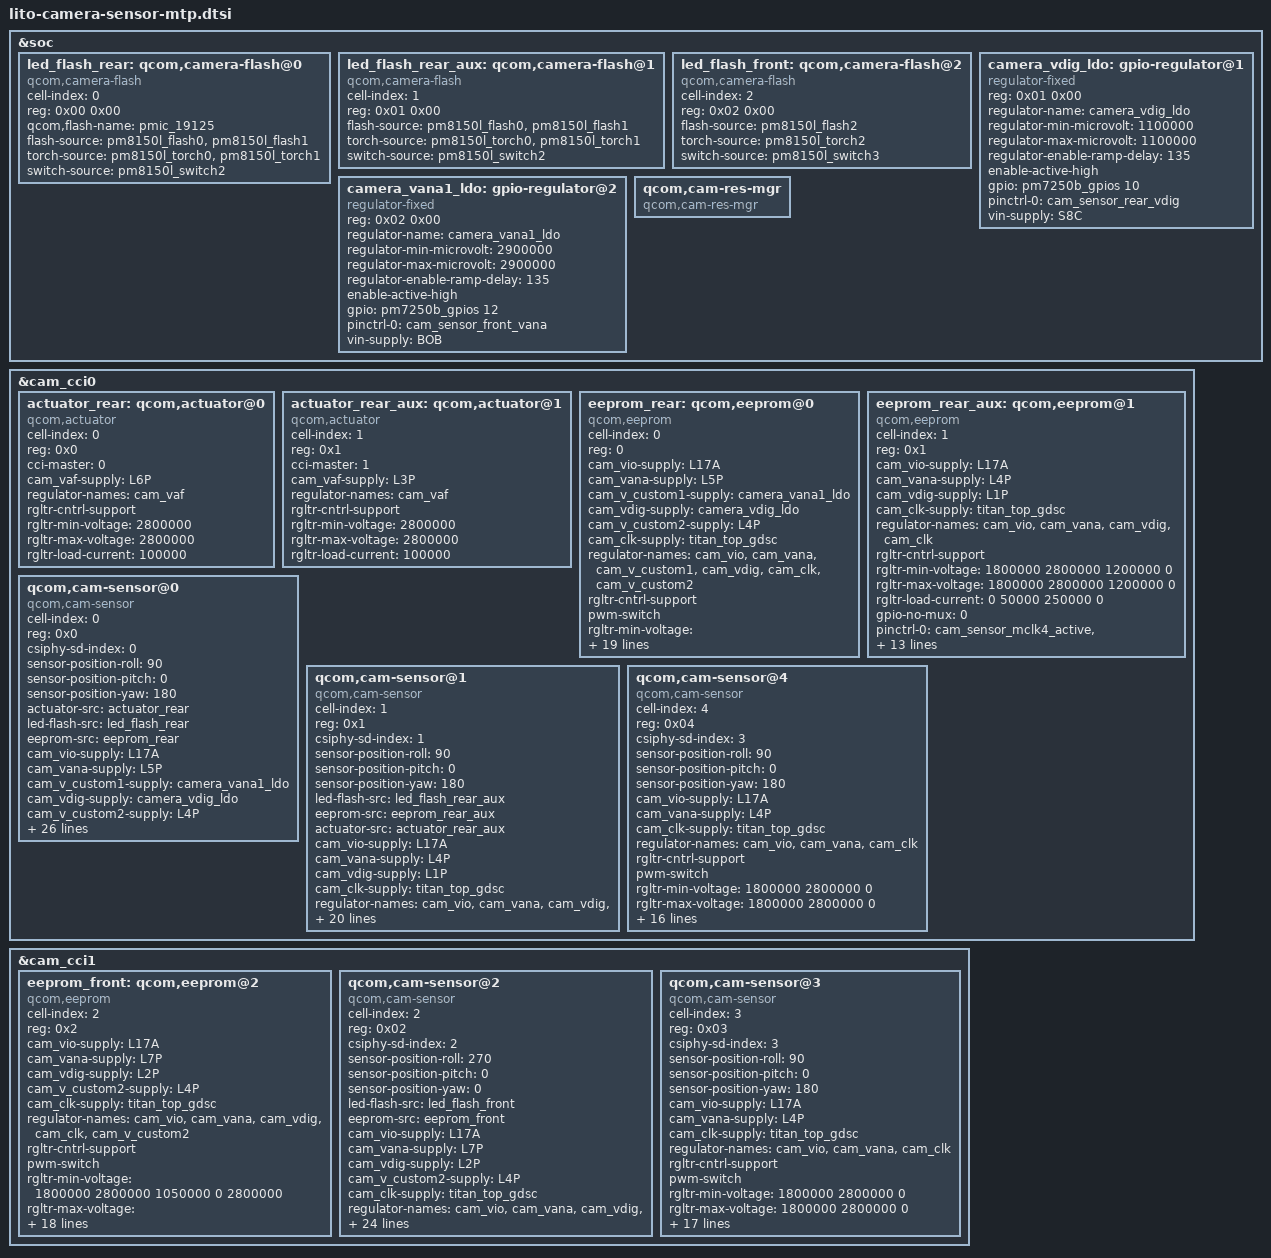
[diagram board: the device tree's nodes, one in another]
#include <dt-bindings/clock/qcom,camcc-lito.h>
/*#ifdef VENDOR_EDIT */
/*
&soc {
	led_flash_rear: qcom,camera-flash@0 {
		cell-index = <0>;
		reg = <0x00 0x00>;
		compatible = "qcom,camera-flash";
		flash-source = <&pm8150l_flash0 &pm8150l_flash1>;
		torch-source = <&pm8150l_torch0 &pm8150l_torch1>;
		switch-source = <&pm8150l_switch2>;
	};

	led_flash_rear_aux: qcom,camera-flash@1 {
		cell-index = <1>;
		reg = <0x01 0x00>;
		compatible = "qcom,camera-flash";
		flash-source = <&pm8150l_flash0 &pm8150l_flash1>;
		torch-source = <&pm8150l_torch0 &pm8150l_torch1>;
		switch-source = <&pm8150l_switch2>;
	};

	qcom,cam-res-mgr {
		compatible = "qcom,cam-res-mgr";
		status = "ok";
	};
};

&cam_cci0 {
	actuator_rear: qcom,actuator@0 {
		cell-index = <0>;
		reg = <0x0>;
		compatible = "qcom,actuator";
		cci-master = <0>;
		cam_vaf-supply = <&L5P>;
		regulator-names = "cam_vaf";
		rgltr-cntrl-support;
		rgltr-min-voltage = <2800000>;
		rgltr-max-voltage = <2800000>;
		rgltr-load-current = <100000>;
		status = "ok";
	};

	eeprom_rear: qcom,eeprom@0 {
		cell-index = <0>;
		reg = <0>;
		compatible = "qcom,eeprom";
		cam_vio-supply = <&L7P>;
		cam_vana-supply = <&L4P>;
		cam_vdig-supply = <&L2P>;
		cam_clk-supply = <&titan_top_gdsc>;
		cam_vaf-supply = <&L5P>;
		regulator-names = "cam_vio", "cam_vana", "cam_vdig",
			"cam_clk", "cam_vaf";
		rgltr-cntrl-support;
		rgltr-min-voltage = <1800000 2800000 1104000 0 2800000>;
		rgltr-max-voltage = <1800000 2800000 1104000 0 2800000>;
		rgltr-load-current = <0 80000 105000 0 100000>;
		gpio-no-mux = <0>;
		pinctrl-names = "cam_default", "cam_suspend";
		pinctrl-0 = <&cam_sensor_mclk0_active
				&cam_sensor_active_rear>;
		pinctrl-1 = <&cam_sensor_mclk0_suspend
				&cam_sensor_suspend_rear>;
		gpios = <&tlmm 13 0>,
			<&tlmm 30 0>;
		gpio-reset = <1>;
		gpio-req-tbl-num = <0 1>;
		gpio-req-tbl-flags = <1 0>;
		gpio-req-tbl-label = "CAMIF_MCLK0",
					"CAM_RESET0";
		sensor-position = <0>;
		sensor-mode = <0>;
		cci-master = <0>;
		status = "ok";
		clocks = <&camcc CAM_CC_MCLK0_CLK>;
		clock-names = "cam_clk";
		clock-cntl-level = "turbo";
		clock-rates = <24000000>;
	};

	eeprom_rear_aux: qcom,eeprom@1 {
		cell-index = <1>;
		reg = <0x1>;
		compatible = "qcom,eeprom";
		cam_vio-supply = <&L7P>;
		cam_vana-supply = <&L3P>;
		cam_vdig-supply = <&S8C>;
		cam_clk-supply = <&titan_top_gdsc>;
		regulator-names = "cam_vio", "cam_vana", "cam_vdig",
			"cam_clk";
		rgltr-cntrl-support;
		rgltr-min-voltage = <1800000 2800000 1350000 0>;
		rgltr-max-voltage = <1800000 2800000 1350000 0>;
		rgltr-load-current = <0 80000 1200000 0>;
		gpio-no-mux = <0>;
		pinctrl-names = "cam_default", "cam_suspend";
		pinctrl-0 = <&cam_sensor_mclk1_active
				 &cam_sensor_active_rear_aux>;
		pinctrl-1 = <&cam_sensor_mclk1_suspend
				 &cam_sensor_suspend_rear_aux>;
		gpios = <&tlmm 14 0>,
			<&tlmm 29 0>,
			<&tlmm 71 0>;
		gpio-reset = <1>;
		gpio-vdig = <2>;
		gpio-req-tbl-num = <0 1 2>;
		gpio-req-tbl-flags = <1 0 0>;
		gpio-req-tbl-label = "CAMIF_MCLK1",
					"CAM_RESET1",
					"CAM_VDIG1";
		sensor-position = <0>;
		sensor-mode = <0>;
		cci-master = <1>;
		clocks = <&camcc CAM_CC_MCLK1_CLK>;
		clock-names = "cam_clk";
		clock-cntl-level = "turbo";
		clock-rates = <24000000>;
		status="ok";
	};

	qcom,cam-sensor@0 {
		cell-index = <0>;
		compatible = "qcom,cam-sensor";
		reg = <0x0>;
		csiphy-sd-index = <0>;
		sensor-position-roll = <90>;
		sensor-position-pitch = <0>;
		sensor-position-yaw = <180>;
		actuator-src = <&actuator_rear>;
		led-flash-src = <&led_flash_rear>;
		eeprom-src = <&eeprom_rear>;
		cam_vio-supply = <&L7P>;
		cam_vana-supply = <&L4P>;
		cam_vdig-supply = <&L2P>;
		cam_clk-supply = <&titan_top_gdsc>;
		regulator-names = "cam_vio", "cam_vana", "cam_vdig",
			"cam_clk";
		rgltr-cntrl-support;
		pwm-switch;
		rgltr-min-voltage = <1800000 2800000 1104000 0>;
		rgltr-max-voltage = <1800000 2800000 1104000 0>;
		rgltr-load-current = <0 80000 105000 0>;
		gpio-no-mux = <0>;
		pinctrl-names = "cam_default", "cam_suspend";
		pinctrl-0 = <&cam_sensor_mclk0_active
				&cam_sensor_active_rear>;
		pinctrl-1 = <&cam_sensor_mclk0_suspend
				&cam_sensor_suspend_rear>;
		gpios = <&tlmm 13 0>,
			<&tlmm 30 0>;
		gpio-reset = <1>;
		gpio-req-tbl-num = <0 1>;
		gpio-req-tbl-flags = <1 0>;
		gpio-req-tbl-label = "CAMIF_MCLK0",
					"CAM_RESET0";
		sensor-mode = <0>;
		cci-master = <0>;
		status = "ok";
		clocks = <&camcc CAM_CC_MCLK0_CLK>;
		clock-names = "cam_clk";
		clock-cntl-level = "turbo";
		clock-rates = <24000000>;
	};

	qcom,cam-sensor@1 {
		cell-index = <1>;
		compatible = "qcom,cam-sensor";
		reg = <0x1>;
		csiphy-sd-index = <1>;
		sensor-position-roll = <90>;
		sensor-position-pitch = <0>;
		sensor-position-yaw = <180>;
		led-flash-src = <&led_flash_rear_aux>;
		eeprom-src = <&eeprom_rear_aux>;
		cam_vio-supply = <&L7P>;
		cam_vana-supply = <&L3P>;
		cam_vdig-supply = <&S8C>;
		cam_clk-supply = <&titan_top_gdsc>;
		regulator-names = "cam_vio", "cam_vana", "cam_vdig",
			"cam_clk";
		rgltr-cntrl-support;
		pwm-switch;
		rgltr-min-voltage = <1800000 2800000 1350000 0>;
		rgltr-max-voltage = <1800000 2800000 1350000 0>;
		rgltr-load-current = <0 80000 1200000 0>;
		gpio-no-mux = <0>;
		pinctrl-names = "cam_default", "cam_suspend";
		pinctrl-0 = <&cam_sensor_mclk1_active
				&cam_sensor_active_rear_aux>;
		pinctrl-1 = <&cam_sensor_mclk1_suspend
				&cam_sensor_suspend_rear_aux>;
		gpios = <&tlmm 14 0>,
			<&tlmm 29 0>,
			<&tlmm 71 0>;
		gpio-reset = <1>;
		gpio-vdig = <2>;
		gpio-req-tbl-num = <0 1 2>;
		gpio-req-tbl-flags = <1 0 0>;
		gpio-req-tbl-label = "CAMIF_MCLK1",
					"CAM_RESET1",
					"CAM_VDIG1";
		sensor-mode = <0>;
		cci-master = <1>;
		clocks = <&camcc CAM_CC_MCLK1_CLK>;
		clock-names = "cam_clk";
		clock-cntl-level = "turbo";
		status = "ok";
		clock-rates = <24000000>;
	};
};

&cam_cci1 {
	eeprom_front: qcom,eeprom@2 {
		cell-index = <2>;
		reg = <0x2>;
		compatible = "qcom,eeprom";
		cam_vio-supply = <&L7P>;
		cam_vana-supply = <&L3P>;
		cam_vdig-supply = <&L1P>;
		cam_clk-supply = <&titan_top_gdsc>;
		regulator-names = "cam_vio", "cam_vana", "cam_vdig",
			"cam_clk";
		rgltr-cntrl-support;
		rgltr-min-voltage = <1800000 2800000 1056000 0>;
		rgltr-max-voltage = <1800000 2800000 1056000 0>;
		rgltr-load-current = <0 80000 105000 0>;
		gpio-no-mux = <0>;
		pinctrl-names = "cam_default", "cam_suspend";
		pinctrl-0 = <&cam_sensor_mclk2_active
				 &cam_sensor_active_front>;
		pinctrl-1 = <&cam_sensor_mclk2_suspend
				 &cam_sensor_suspend_front>;
		gpios = <&tlmm 15 0>,
			<&tlmm 32 0>;
		gpio-reset = <1>;
		gpio-req-tbl-num = <0 1>;
		gpio-req-tbl-flags = <1 0>;
		gpio-req-tbl-label = "CAMIF_MCLK2",
					"CAM_RESET2";
		sensor-position = <1>;
		sensor-mode = <0>;
		cci-device = <1>;
		cci-master = <0>;
		status = "ok";
		clocks = <&camcc CAM_CC_MCLK2_CLK>;
		clock-names = "cam_clk";
		clock-cntl-level = "turbo";
		clock-rates = <24000000>;
	};

	qcom,cam-sensor@2 {
		cell-index = <2>;
		compatible = "qcom,cam-sensor";
		reg = <0x02>;
		csiphy-sd-index = <2>;
		sensor-position-roll = <270>;
		sensor-position-pitch = <0>;
		sensor-position-yaw = <0>;
		eeprom-src = <&eeprom_front>;
		cam_vio-supply = <&L7P>;
		cam_vana-supply = <&L3P>;
		cam_vdig-supply = <&L1P>;
		cam_clk-supply = <&titan_top_gdsc>;
		regulator-names = "cam_vio", "cam_vana", "cam_vdig",
			"cam_clk";
		rgltr-cntrl-support;
		pwm-switch;
		rgltr-min-voltage = <1800000 2800000 1056000 0>;
		rgltr-max-voltage = <1800000 2800000 1056000 0>;
		rgltr-load-current = <0 80000 105000 0>;
		gpio-no-mux = <0>;
		pinctrl-names = "cam_default", "cam_suspend";
		pinctrl-0 = <&cam_sensor_mclk2_active
				 &cam_sensor_active_front>;
		pinctrl-1 = <&cam_sensor_mclk2_suspend
				 &cam_sensor_suspend_front>;
		gpios = <&tlmm 15 0>,
			<&tlmm 32 0>;
		gpio-reset = <1>;
		gpio-req-tbl-num = <0 1>;
		gpio-req-tbl-flags = <1 0>;
		gpio-req-tbl-label = "CAMIF_MCLK2",
					"CAM_RESET2";
		sensor-mode = <0>;
		cci-device = <1>;
		cci-master = <0>;
		status = "ok";
		clocks = <&camcc CAM_CC_MCLK2_CLK>;
		clock-names = "cam_clk";
		clock-cntl-level = "turbo";
		clock-rates = <24000000>;
	};
};
*/
&soc {
	led_flash_rear: qcom,camera-flash@0 {
		cell-index = <0>;
		reg = <0x00 0x00>;
		compatible = "qcom,camera-flash";
		qcom,flash-name = "pmic_19125";
		flash-source = <&pm8150l_flash0 &pm8150l_flash1>;
		torch-source = <&pm8150l_torch0 &pm8150l_torch1>;
		switch-source = <&pm8150l_switch2>;
	};

	led_flash_rear_aux: qcom,camera-flash@1 {
		cell-index = <1>;
		reg = <0x01 0x00>;
		compatible = "qcom,camera-flash";
		flash-source = <&pm8150l_flash0 &pm8150l_flash1>;
		torch-source = <&pm8150l_torch0 &pm8150l_torch1>;
		switch-source = <&pm8150l_switch2>;
	};

	led_flash_front: qcom,camera-flash@2 {
		cell-index = <2>;
		reg = <0x02 0x00>;
		compatible = "qcom,camera-flash";
		flash-source = <&pm8150l_flash2>;
		torch-source = <&pm8150l_torch2>;
		switch-source = <&pm8150l_switch3>;
		status = "ok";
	};
/*
	camera_vio_ldo: gpio-regulator@0 {
		compatible = "regulator-fixed";
		reg = <0x00 0x00>;
		regulator-name = "camera_vio_ldo";
		regulator-min-microvolt = <1800000>;
		regulator-max-microvolt = <1800000>;
		regulator-enable-ramp-delay = <135>;
		enable-active-high;
		gpio = <&tlmm 83 0>;
		pinctrl-names = "default";
		pinctrl-0 = <&cam_sensor_rear_vio>;
		vin-supply = <&L5P>;
	};
*/
    camera_vdig_ldo: gpio-regulator@1 {
		compatible = "regulator-fixed";
		reg = <0x01 0x00>;
		regulator-name = "camera_vdig_ldo";
		regulator-min-microvolt = <1100000>;
		regulator-max-microvolt = <1100000>;
		regulator-enable-ramp-delay = <135>;
		enable-active-high;
		gpio = <&pm7250b_gpios 10 0>;
		pinctrl-names = "default";
		pinctrl-0 = <&cam_sensor_rear_vdig>;
		vin-supply = <&S8C>;
	};

	camera_vana1_ldo: gpio-regulator@2 {
		compatible = "regulator-fixed";
		reg = <0x02 0x00>;
		regulator-name = "camera_vana1_ldo";
		regulator-min-microvolt = <2900000>;
		regulator-max-microvolt = <2900000>;
		regulator-enable-ramp-delay = <135>;
		enable-active-high;
		gpio = <&pm7250b_gpios 12 0>;
		pinctrl-names = "default";
		pinctrl-0 = <&cam_sensor_front_vana>;
		vin-supply = <&BOB>;
	};
/*
	camera_vana2_ldo: gpio-regulator@3 {
		compatible = "regulator-fixed";
		reg = <0x03 0x00>;
		regulator-name = "camera_vana2_ldo";
		regulator-min-microvolt = <2800000>;
		regulator-max-microvolt = <2800000>;
		regulator-enable-ramp-delay = <135>;
		enable-active-high;
		gpio = <&pm7250b_gpios 2 0>;
		pinctrl-names = "default";
		pinctrl-0 = <&cam_sensor_rear2_vana>;
		vin-supply = <&BOB>;
	};
*/
	qcom,cam-res-mgr {
		compatible = "qcom,cam-res-mgr";
		status = "ok";
	};
};
&cam_cci0 {
	actuator_rear: qcom,actuator@0 {
		cell-index = <0>;
		reg = <0x0>;
		compatible = "qcom,actuator";
		cci-master = <0>;
		cam_vaf-supply = <&L6P>;
		regulator-names = "cam_vaf";
		rgltr-cntrl-support;
		rgltr-min-voltage = <2800000>;
		rgltr-max-voltage = <2800000>;
		rgltr-load-current = <100000>;
		status = "ok";
	};
	actuator_rear_aux: qcom,actuator@1 {
		cell-index = <1>;
		reg = <0x1>;
		compatible = "qcom,actuator";
		cci-master = <1>;
		cam_vaf-supply = <&L3P>;
		regulator-names = "cam_vaf";
		rgltr-cntrl-support;
		rgltr-min-voltage = <2800000>;
		rgltr-max-voltage = <2800000>;
		rgltr-load-current = <100000>;
		status = "ok";
	};
/*
	actuator_rear_aux2: qcom,actuator@2 {
		cell-index = <2>;
		reg = <0x2>;
		compatible = "qcom,actuator";
		cci-device = <1>;
		cci-master = <0>;
		cam_vaf-supply = <&L3P>;
		regulator-names = "cam_vaf";
		rgltr-cntrl-support;
		rgltr-min-voltage = <2800000>;
		rgltr-max-voltage = <2800000>;
		rgltr-load-current = <100000>;
		status = "ok";
	};

	ois_rear: qcom,ois@0 {
		cell-index = <0>;
		reg = <0x0>;
		compatible = "qcom,ois";
		cci-master = <0>;
		cam_vdig-supply = <&L6P>;
		regulator-names = "cam_vdig";
		rgltr-cntrl-support;
		rgltr-min-voltage = <2800000>;
		rgltr-max-voltage = <2800000>;
		rgltr-load-current = <0>;
		status = "ok";
	};
*/
	eeprom_rear: qcom,eeprom@0 {
		cell-index = <0>;
		reg = <0>;
		compatible = "qcom,eeprom";
		cam_vio-supply = <&L17A>;
		cam_vana-supply = <&L5P>;
		cam_v_custom1-supply = <&camera_vana1_ldo>;
		cam_vdig-supply = <&camera_vdig_ldo>;
		cam_v_custom2-supply = <&L4P>;
		cam_clk-supply = <&titan_top_gdsc>;
		regulator-names = "cam_vio", "cam_vana", "cam_v_custom1", "cam_vdig",
			"cam_clk", "cam_v_custom2";
		rgltr-cntrl-support;
		pwm-switch;
		rgltr-min-voltage = <1800000 1800000 2900000 1100000 0 2800000>;
		rgltr-max-voltage = <1800000 1800000 2900000 1100000 0 2800000>;
		rgltr-load-current = <0 0 60000 105000 0 80000>;
		gpio-no-mux = <0>;
		pinctrl-names = "cam_default", "cam_suspend";
		pinctrl-0 = <&cam_sensor_mclk0_active
				&cam_sensor_active_rear>;
		pinctrl-1 = <&cam_sensor_mclk0_suspend
				&cam_sensor_suspend_rear>;
		gpios = <&tlmm 13 0>,
			<&tlmm 30 0>;
		gpio-reset = <1>;
		gpio-req-tbl-num = <0 1>;
		gpio-req-tbl-flags = <1 0>;
		gpio-req-tbl-label = "CAMIF_MCLK0",
					"CAM_RESET0";
		sensor-mode = <0>;
		cci-master = <0>;
		status = "ok";
		clocks = <&camcc CAM_CC_MCLK0_CLK>;
		clock-names = "cam_clk";
		clock-cntl-level = "turbo";
		clock-rates = <24000000>;
	};

	eeprom_rear_aux: qcom,eeprom@1 {
		cell-index = <1>;
		reg = <0x1>;
		compatible = "qcom,eeprom";
		cam_vio-supply = <&L17A>;
		cam_vana-supply = <&L4P>;
		cam_vdig-supply = <&L1P>;
		cam_clk-supply = <&titan_top_gdsc>;
		regulator-names = "cam_vio", "cam_vana", "cam_vdig",
			"cam_clk";
		rgltr-cntrl-support;
		//pwm-switch;
		rgltr-min-voltage = <1800000 2800000 1200000 0>;
		rgltr-max-voltage = <1800000 2800000 1200000 0>;
		rgltr-load-current = <0 50000 250000 0>;
		gpio-no-mux = <0>;
		pinctrl-names = "cam_default", "cam_suspend";
		pinctrl-0 = <&cam_sensor_mclk4_active
				&cam_sensor_active_rear_aux>;
		pinctrl-1 = <&cam_sensor_mclk4_suspend
				&cam_sensor_suspend_rear_aux>;
		gpios = <&tlmm 25 0>,
			<&tlmm 21 0>;
		gpio-reset = <1>;
		gpio-req-tbl-num = <0 1>;
		gpio-req-tbl-flags = <1 0>;
		gpio-req-tbl-label = "CAMIF_MCLK1",
					"CAM_RESET1";
		sensor-mode = <0>;
		cci-master = <1>;
		clocks = <&camcc CAM_CC_MCLK4_CLK>;
		clock-names = "cam_clk";
		clock-cntl-level = "turbo";
		status = "ok";
		clock-rates = <24000000>;
	};

	qcom,cam-sensor@0 {
		cell-index = <0>;
		compatible = "qcom,cam-sensor";
		reg = <0x0>;
		csiphy-sd-index = <0>;
		sensor-position-roll = <90>;
		sensor-position-pitch = <0>;
		sensor-position-yaw = <180>;
		actuator-src = <&actuator_rear>;
		led-flash-src = <&led_flash_rear>;
		eeprom-src = <&eeprom_rear>;
		//ois-src = <&ois_rear>;
		cam_vio-supply = <&L17A>;
		cam_vana-supply = <&L5P>;
		cam_v_custom1-supply = <&camera_vana1_ldo>;
		cam_vdig-supply = <&camera_vdig_ldo>;
		cam_v_custom2-supply = <&L4P>;
		cam_clk-supply = <&titan_top_gdsc>;
		regulator-names = "cam_vio", "cam_vana", "cam_v_custom1", "cam_vdig",
			"cam_clk", "cam_v_custom2";
		rgltr-cntrl-support;
		pwm-switch;
		rgltr-min-voltage = <1800000 1800000 2900000 1100000 0 2800000>;
		rgltr-max-voltage = <1800000 1800000 2900000 1100000 0 2800000>;
		rgltr-load-current = <0 0 60000 105000 0 80000>;
		gpio-no-mux = <0>;
		pinctrl-names = "cam_default", "cam_suspend";
		pinctrl-0 = <&cam_sensor_mclk0_active
				&cam_sensor_active_rear>;
		pinctrl-1 = <&cam_sensor_mclk0_suspend
				&cam_sensor_suspend_rear>;
		gpios = <&tlmm 13 0>,
			<&tlmm 30 0>;
		gpio-reset = <1>;
		gpio-req-tbl-num = <0 1>;
		gpio-req-tbl-flags = <1 0>;
		gpio-req-tbl-label = "CAMIF_MCLK0",
					"CAM_RESET0";
		sensor-mode = <0>;
		cci-master = <0>;
		status = "ok";
		clocks = <&camcc CAM_CC_MCLK0_CLK>;
		clock-names = "cam_clk";
		clock-cntl-level = "turbo";
		clock-rates = <24000000>;
	};

	qcom,cam-sensor@1 {
		cell-index = <1>;
		compatible = "qcom,cam-sensor";
		reg = <0x1>;
		csiphy-sd-index = <1>;
		sensor-position-roll = <90>;
		sensor-position-pitch = <0>;
		sensor-position-yaw = <180>;
		led-flash-src = <&led_flash_rear_aux>;
		eeprom-src = <&eeprom_rear_aux>;
		actuator-src = <&actuator_rear_aux>;
		cam_vio-supply = <&L17A>;
		cam_vana-supply = <&L4P>;
		cam_vdig-supply = <&L1P>;
		cam_clk-supply = <&titan_top_gdsc>;
		regulator-names = "cam_vio", "cam_vana", "cam_vdig",
			"cam_clk";
		rgltr-cntrl-support;
		//pwm-switch;
		rgltr-min-voltage = <1800000 2800000 1200000 0>;
		rgltr-max-voltage = <1800000 2800000 1200000 0>;
		rgltr-load-current = <0 50000 250000 0>;
		gpio-no-mux = <0>;
		pinctrl-names = "cam_default", "cam_suspend";
		pinctrl-0 = <&cam_sensor_mclk4_active
				&cam_sensor_active_rear_aux>;
		pinctrl-1 = <&cam_sensor_mclk4_suspend
				&cam_sensor_suspend_rear_aux>;
		gpios = <&tlmm 25 0>,
			<&tlmm 21 0>;
		gpio-reset = <1>;
		gpio-req-tbl-num = <0 1>;
		gpio-req-tbl-flags = <1 0>;
		gpio-req-tbl-label = "CAMIF_MCLK1",
					"CAM_RESET1";
		sensor-mode = <0>;
		cci-master = <1>;
		clocks = <&camcc CAM_CC_MCLK4_CLK>;
		clock-names = "cam_clk";
		clock-cntl-level = "turbo";
		status = "ok";
		clock-rates = <24000000>;
	};
	qcom,cam-sensor@4 {
		cell-index = <4>;
		compatible = "qcom,cam-sensor";
		reg = <0x04>;
		csiphy-sd-index = <3>;
		sensor-position-roll = <90>;
		sensor-position-pitch = <0>;
		sensor-position-yaw = <180>;
		cam_vio-supply = <&L17A>;
		cam_vana-supply = <&L4P>;
		cam_clk-supply = <&titan_top_gdsc>;
		regulator-names = "cam_vio", "cam_vana",
			"cam_clk";
		rgltr-cntrl-support;
		pwm-switch;
		rgltr-min-voltage = <1800000 2800000 0>;
		rgltr-max-voltage = <1800000 2800000 0>;
		rgltr-load-current = <0 80000 0>;
		gpio-no-mux = <0>;
		pinctrl-names = "cam_default", "cam_suspend";
		pinctrl-0 = <&cam_sensor_mclk3_active
				 &cam_sensor_active_triple_rear_aux>;
		pinctrl-1 = <&cam_sensor_mclk3_suspend
				 &cam_sensor_suspend_triple_rear_aux>;
		gpios = <&tlmm 16 0>,
			<&tlmm 23 0>;
		gpio-reset = <1>;
		gpio-req-tbl-num = <0 1>;
		gpio-req-tbl-flags = <1 0>;
		gpio-req-tbl-label = "CAMIF_MCLK4",
					"CAM_RESET4";
		sensor-mode = <0>;
		//cci-device = <1>;
		cci-master = <1>;
		status = "ok";
		clocks = <&camcc CAM_CC_MCLK3_CLK>;
		clock-names = "cam_clk";
		clock-cntl-level = "turbo";
		clock-rates = <24000000>;
	};

};
&cam_cci1 {
	eeprom_front: qcom,eeprom@2 {
		cell-index = <2>;
		reg = <0x2>;
		compatible = "qcom,eeprom";
		cam_vio-supply = <&L17A>;
		cam_vana-supply = <&L7P>;
		cam_vdig-supply = <&L2P>;
		cam_v_custom2-supply = <&L4P>;
		cam_clk-supply = <&titan_top_gdsc>;
		regulator-names = "cam_vio", "cam_vana", "cam_vdig",
			"cam_clk", "cam_v_custom2";
		rgltr-cntrl-support;
		pwm-switch;
		rgltr-min-voltage = <1800000 2800000 1050000 0 2800000>;
		rgltr-max-voltage = <1800000 2800000 1050000 0 2800000>;
		rgltr-load-current = <0 80000 105000 0 80000>;
		gpio-no-mux = <0>;
		pinctrl-names = "cam_default", "cam_suspend";
		pinctrl-0 = <&cam_sensor_mclk2_active
				 &cam_sensor_active_front>;
		pinctrl-1 = <&cam_sensor_mclk2_suspend
				 &cam_sensor_suspend_front>;
		gpios = <&tlmm 15 0>,
			<&tlmm 32 0>;
		gpio-reset = <1>;
		gpio-req-tbl-num = <0 1>;
		gpio-req-tbl-flags = <1 0>;
		gpio-req-tbl-label = "CAMIF_MCLK2",
					"CAM_RESET2";
		sensor-mode = <0>;
		cci-device = <1>;
		cci-master = <0>;
		status = "ok";
		clocks = <&camcc CAM_CC_MCLK2_CLK>;
		clock-names = "cam_clk";
		clock-cntl-level = "turbo";
		clock-rates = <24000000>;
	};
/*
	eeprom_rear_aux2: qcom,eeprom@3 {
		cell-index = <3>;
		reg = <0x3>;
		compatible = "qcom,eeprom";
		cam_vio-supply = <&L17A>;
		cam_vana-supply = <&camera_vana2_ldo>;
		cam_vdig-supply = <&L2P>;
		cam_clk-supply = <&titan_top_gdsc>;
		regulator-names = "cam_vio", "cam_vana", "cam_vdig",
			"cam_clk";
		rgltr-cntrl-support;
		pwm-switch;
		rgltr-min-voltage = <1800000 2800000 1050000 0>;
		rgltr-max-voltage = <1800000 2800000 1050000 0>;
		rgltr-load-current = <0 80000 105000 0>;
		gpio-no-mux = <0>;
		pinctrl-names = "cam_default", "cam_suspend";
		pinctrl-0 = <&cam_sensor_mclk1_active
				 &cam_sensor_active_rear_aux2>;
		pinctrl-1 = <&cam_sensor_mclk1_suspend
				 &cam_sensor_suspend_rear_aux2>;
		gpios = <&tlmm 14 0>,
			<&tlmm 29 0>;
		gpio-reset = <1>;
		gpio-req-tbl-num = <0 1>;
		gpio-req-tbl-flags = <1 0>;
		gpio-req-tbl-label = "CAMIF_MCLK3",
					"CAM_RESET3";
		sensor-mode = <0>;
		cci-device = <1>;
		cci-master = <0>;
		status = "ok";
		clocks = <&camcc CAM_CC_MCLK1_CLK>;
		clock-names = "cam_clk";
		clock-cntl-level = "turbo";
		clock-rates = <24000000>;
	};
*/
	qcom,cam-sensor@2 {
		cell-index = <2>;
		compatible = "qcom,cam-sensor";
		reg = <0x02>;
		csiphy-sd-index = <2>;
		sensor-position-roll = <270>;
		sensor-position-pitch = <0>;
		sensor-position-yaw = <0>;
		led-flash-src = <&led_flash_front>;
		eeprom-src = <&eeprom_front>;
		cam_vio-supply = <&L17A>;
		cam_vana-supply = <&L7P>;
		cam_vdig-supply = <&L2P>;
		cam_v_custom2-supply = <&L4P>;
		cam_clk-supply = <&titan_top_gdsc>;
		regulator-names = "cam_vio", "cam_vana", "cam_vdig",
			"cam_clk", "cam_v_custom2";
		rgltr-cntrl-support;
		pwm-switch;
		rgltr-min-voltage = <1800000 2800000 1050000 0 2800000>;
		rgltr-max-voltage = <1800000 2800000 1050000 0 2800000>;
		rgltr-load-current = <0 80000 105000 0 80000>;
		gpio-no-mux = <0>;
		pinctrl-names = "cam_default", "cam_suspend";
		pinctrl-0 = <&cam_sensor_mclk2_active
				 &cam_sensor_active_front>;
		pinctrl-1 = <&cam_sensor_mclk2_suspend
				 &cam_sensor_suspend_front>;
		gpios = <&tlmm 15 0>,
			<&tlmm 32 0>;
		gpio-reset = <1>;
		gpio-req-tbl-num = <0 1>;
		gpio-req-tbl-flags = <1 0>;
		gpio-req-tbl-label = "CAMIF_MCLK2",
					"CAM_RESET2";
		sensor-mode = <0>;
		cci-device = <1>;
		cci-master = <0>;
		status = "ok";
		clocks = <&camcc CAM_CC_MCLK2_CLK>;
		clock-names = "cam_clk";
		clock-cntl-level = "turbo";
		clock-rates = <24000000>;
	};
	qcom,cam-sensor@3 {
		cell-index = <3>;
		compatible = "qcom,cam-sensor";
		reg = <0x03>;
		csiphy-sd-index = <3>;
		sensor-position-roll = <90>;
		sensor-position-pitch = <0>;
		sensor-position-yaw = <180>;
		//eeprom-src = <&eeprom_rear_aux2>;
		//actuator-src = <&actuator_rear_aux2>;
		cam_vio-supply = <&L17A>;
		cam_vana-supply = <&L4P>;
		//cam_vdig-supply = <&L2P>;
		cam_clk-supply = <&titan_top_gdsc>;
		regulator-names = "cam_vio", "cam_vana",
			"cam_clk";
		rgltr-cntrl-support;
		pwm-switch;
		rgltr-min-voltage = <1800000 2800000 0>;
		rgltr-max-voltage = <1800000 2800000 0>;
		rgltr-load-current = <0 80000 0>;
		gpio-no-mux = <0>;
		pinctrl-names = "cam_default", "cam_suspend";
		pinctrl-0 = <&cam_sensor_mclk1_active
				 &cam_sensor_active_rear_aux2>;
		pinctrl-1 = <&cam_sensor_mclk1_suspend
				 &cam_sensor_suspend_rear_aux2>;
		gpios = <&tlmm 14 0>,
			<&tlmm 29 0>;
		gpio-reset = <1>;
		gpio-req-tbl-num = <0 1>;
		gpio-req-tbl-flags = <1 0>;
		gpio-req-tbl-label = "CAMIF_MCLK3",
					"CAM_RESET3";
		sensor-mode = <0>;
		cci-device = <1>;
		cci-master = <0>;
		status = "ok";
		clocks = <&camcc CAM_CC_MCLK1_CLK>;
		clock-names = "cam_clk";
		clock-cntl-level = "turbo";
		clock-rates = <24000000>;
	};

};
